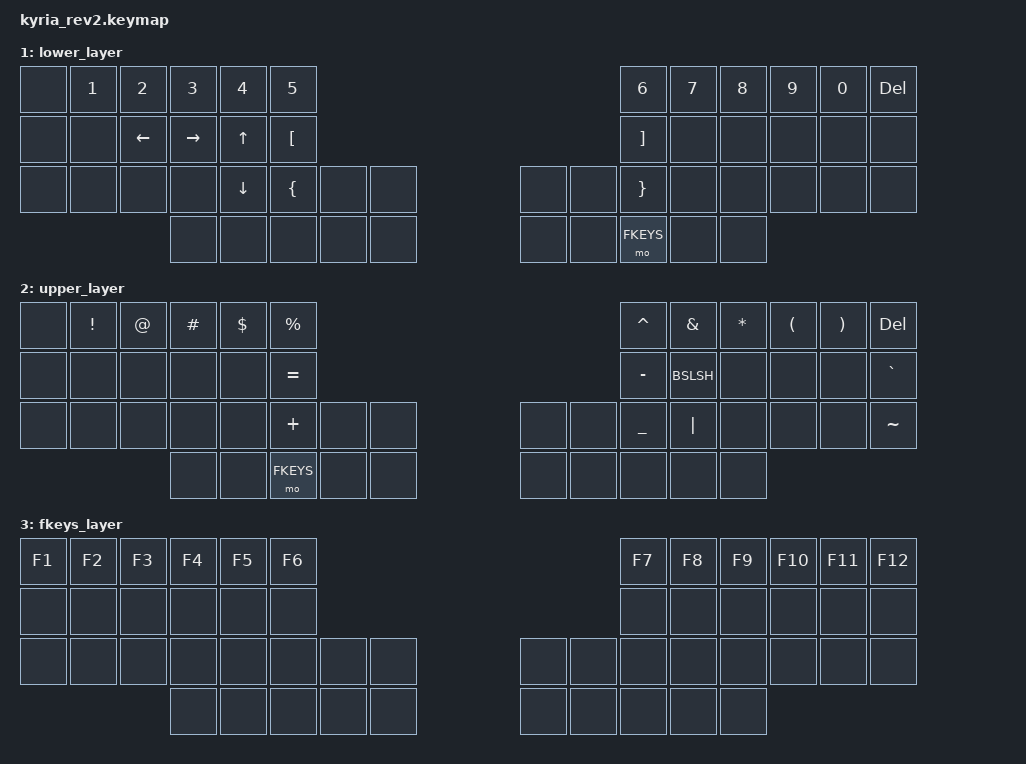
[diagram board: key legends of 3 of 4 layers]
/*
 * Copyright (c) 2020 The ZMK Contributors
 *
 * SPDX-License-Identifier: MIT
 */

#include <behaviors.dtsi>
#include <dt-bindings/zmk/keys.h>

#define DEFAULT 0
#define LOWER   1
#define RAISE   2
#define FKEYS   3

/ {
	keymap {
		compatible = "zmk,keymap";

		default_layer {
// ---------------------------------------------------------------------------------------------------------------------------------
// |  TAB       |  Q  |  W  |  E   |  R   |  T   |                                          |  Y   |  U    |  I    |  O   |   P   |   BKSP  |
// |  CTRL/ESC  |  A  |  S  |  D   |  F   |  G   |                                          |  H   |  J    |  K    |  L   |   ;   |   CTRL/'  |
// | SHIFT      |  Z  |  X  |  C   |  V   |  B   | XXXXXX | HOME |  |  UP   | XXXXXX  |  N    |  M    |  ,    |  .   |   /   | RShift |
//                     | MUTE  | LGUI  | Low  |  RET      | END  |  | DOWN  |  SPACE  | Upper | R-ALT | F-Keys |
			bindings = <
	&kp TAB         &kp Q &kp W &kp E &kp R &kp T                                          &kp Y &kp U  &kp I     &kp O   &kp P    &kp BKSP
	&mt LCTRL ESC   &kp A &kp S &kp D &kp F &kp G                                          &kp H &kp J  &kp K     &kp L   &kp SEMI &mt RCTRL SQT
	&kp LSHFT       &kp Z &kp X &kp C &kp V &kp B &none &kp HOME           &kp PG_UP &none &kp N &kp M  &kp COMMA &kp DOT &kp FSLH &kp RSHFT
	                 &kp C_MUTE &kp LGUI &mo LOWER &kp RET &kp END         s&kp PG_DN &kp SPACE  &mo UPPER &kp RALT &mo FKEYS 
			>;
		};

        lower_layer {
// ---------------------------------------------------------------------------------------------------------------------------------
// |  NONE  |    1   |    2   |    3    |    4    |    5    |                                          |    6    |    7   |    8   |    9    |     0    |    DEL  |
// |  NONE  |  NONE  |  LEFT  |  RIGHT  |    UP   |  LBRC   |                                          |  RBRC   |  NONE  |  NONE  |  NONE   |   NONE   |   NONE  |
// |  NONE  |  NONE  |  NONE  |  NONE   |  DOWN   |  LCBR   |  NONE | NONE |           |  NONE  | NONE |  RCBR   |  NONE  |  NONE  |  NONE   |   NONE   |   NONE  |
//                                  | NONE  | NONE  | NONE  |  NONE | NONE |           |  NONE  | NONE | NONE | NONE | NONE |
            bindings = <
    &none &kp N1 &kp N2   &kp N3    &kp N4    &kp N5                                                    &kp N6    &kp N7 &kp N8 &kp N9 &kp N0 &kp DEL
    &none &none  &kp LEFT &kp RIGHT &kp UP    &kp LBKT                                                  &kp RBKT  &none  &none  &none  &none  &none
    &none &none  &none    &none     &kp DOWN  &kp LBRC  &none &none                        &none &none  &kp RBRC  &none  &none  &none  &none  &none
                          &none     &none     &none     &none &none                        &none &none  &mo FKEYS &none  &none
            >;
        };


        upper_layer {
// ---------------------------------------------------------------------------------------------------------------------------------
// |  NONE  |    !   |    @   |    #    |    $    |    %    |                                          |    ^    |    &   |    *   |    (    |     )    |   DEL  |
// |  NONE  |  NONE  |  NONE  |  NONE   |  NONE   |    =    |                                          |    -    |    \   |  NONE  |  NONE   |   NONE   |     `   |
// |  NONE  |  NONE  |  NONE  |  NONE   |  NONE   |    +    |  NONE | NONE |           |  NONE  | NONE |    _    |    |   |  NONE  |  NONE   |   NONE   |     ~   |
//                                  | NONE  | NONE  | NONE  |  NONE | NONE |           |  NONE  | NONE | NONE | NONE | NONE |
                   bindings = <
    &none &kp EXCL &kp AT   &kp HASH    &kp DOLLAR    &kp PRCNT                                        &kp CARET  &kp AMPS   &kp STAR &kp LPAR &kp RPAR &kp DEL
    &none &none    &none    &none       &none         &kp EQUAL                                        &kp MINUS  &kp BSLSH  &none    &none    &none    &kp GRAVE
    &none &none    &none    &none       &none         &kp PLUS  &none &none               &none &none  &kp UNDER  &kp PIPE   &none    &none    &none    &kp TILDE
                            &none       &none         &mo FKEYS &none &none               &none &none  &none     &none &none
            >;
        };

        fkeys_layer {
// ---------------------------------------------------------------------------------------------------------------------------------
// |    F1  |    F2  |    F3  |    F4   |    F5   |    F6   |                                          |    F7   |    F8  |    F9  |   F10   |    F11   |    F12  |
// |  NONE  |  NONE  |  NONE  |  NONE   |  NONE   |  NONE   |                                          |  NONE   |  NONE  |  NONE  |  NONE   |   NONE   |   NONE  |
// |  NONE  |  NONE  |  NONE  |  NONE   |  NONE   |  NONE   |  NONE | NONE |           |  NONE  | NONE |  NONE   |  NONE  |  NONE  |  NONE   |   NONE   |   NONE  |
//                                  | NONE  | NONE  | NONE  |  NONE | NONE |           |  NONE  | NONE | NONE | NONE | NONE |
            bindings = <
            &kp F1  &kp F2  &kp F3  &kp F4  &kp F5  &kp F6                                              &kp F7  &kp F8  &kp F9  &kp F10  &kp F11  &kp F12
            &none   &none   &none   &none   &none   &none                                               &none   &none   &none   &none    &none    &none
            &none   &none   &none   &none   &none   &none   &none &none                    &none &none  &none   &none   &none   &none    &none    &none
                                    &none   &none   &none   &none &none                    &none &none  &none   &none   &none
            >;
        };

// ---------------------------------------------------------------------------------------------------------------------------------
// |  NONE  |  NONE  |  NONE  |  NONE   |  NONE   |  NONE   |                                          |  NONE   |  NONE  |  NONE  |  NONE   |   NONE   |   NONE  |
// |  NONE  |  NONE  |  NONE  |  NONE   |  NONE   |  NONE   |                                          |  NONE   |  NONE  |  NONE  |  NONE   |   NONE   |   NONE  |
// |  NONE  |  NONE  |  NONE  |  NONE   |  NONE   |  NONE   |  NONE | NONE |           |  NONE  | NONE |  NONE   |  NONE  |  NONE  |  NONE   |   NONE   |   NONE  |
//                                  | NONE  | NONE  | NONE  |  NONE | NONE |           |  NONE  | NONE | NONE | NONE | NONE |
};
